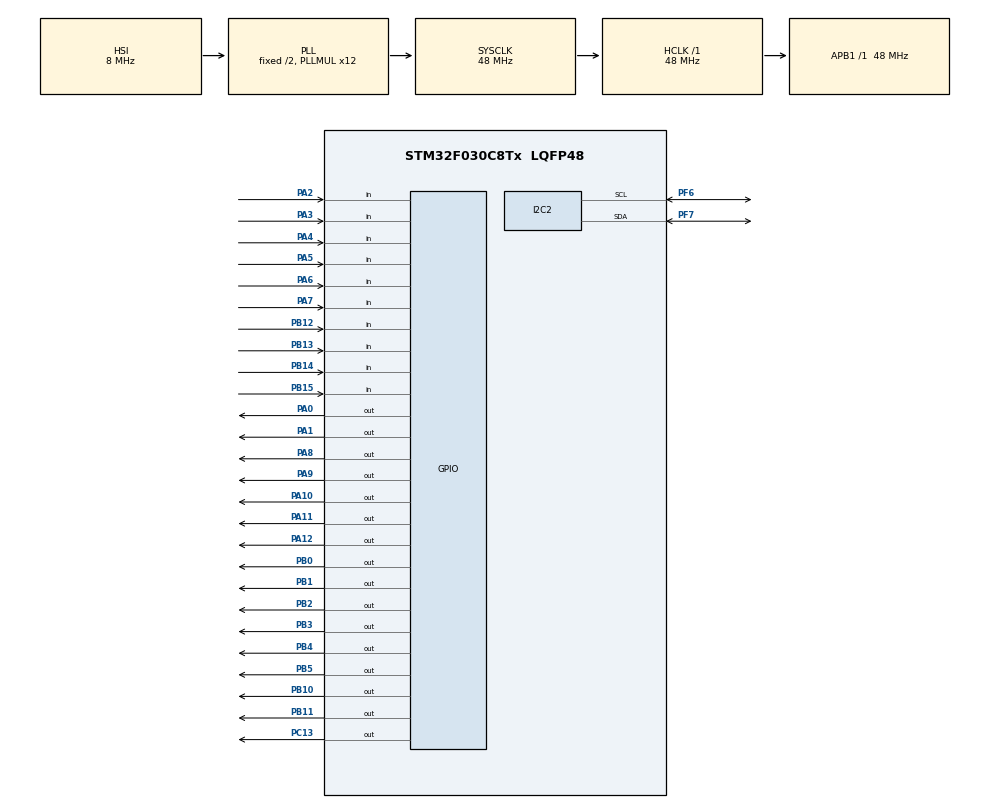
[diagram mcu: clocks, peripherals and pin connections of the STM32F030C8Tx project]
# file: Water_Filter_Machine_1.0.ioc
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I2C2.Timing=0x20303E5D
Mcu.Family=STM32F0
Mcu.Name=STM32F030C8Tx
Mcu.Package=LQFP48
PA0.Signal=GPIO_Output
PA1.Signal=GPIO_Output
PA10.Signal=GPIO_Output
PA11.Signal=GPIO_Output
PA12.Signal=GPIO_Output
PA13.Mode=Serial_Wire
PA13.Signal=SYS_SWDIO
PA14.Mode=Serial_Wire
PA14.Signal=SYS_SWCLK
PA2.Signal=GPIO_Input
PA3.Signal=GPIO_Input
PA4.Signal=GPIO_Input
PA5.Signal=GPIO_Input
PA6.Signal=GPIO_Input
PA7.Signal=GPIO_Input
PA8.Signal=GPIO_Output
PA9.Signal=GPIO_Output
PB0.Signal=GPIO_Output
PB1.Signal=GPIO_Output
PB10.Signal=GPIO_Output
PB11.Signal=GPIO_Output
PB12.GPIO_PuPd=GPIO_PULLUP
PB12.Signal=GPIO_Input
PB13.GPIO_PuPd=GPIO_PULLUP
PB13.Signal=GPIO_Input
PB14.GPIO_PuPd=GPIO_PULLUP
PB14.Signal=GPIO_Input
PB15.GPIO_PuPd=GPIO_PULLUP
PB15.Signal=GPIO_Input
PB2.Signal=GPIO_Output
PB3.Signal=GPIO_Output
PB4.Signal=GPIO_Output
PB5.Signal=GPIO_Output
PC13.Signal=GPIO_Output
PF6.Mode=I2C
PF6.Signal=I2C2_SCL
PF7.Mode=I2C
PF7.Signal=I2C2_SDA
ProjectManager.HeapSize=0x200
ProjectManager.StackSize=0x400
ProjectManager.TargetToolchain=STM32CubeIDE
RCC.AHBFreq_Value=48000000
RCC.APB1Freq_Value=48000000
RCC.APB1TimFreq_Value=48000000
RCC.HCLKFreq_Value=48000000
RCC.PLLMUL=RCC_PLL_MUL12
RCC.SYSCLKFreq_VALUE=48000000
RCC.SYSCLKSource=RCC_SYSCLKSOURCE_PLLCLK
board=custom

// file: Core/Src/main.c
/* USER CODE BEGIN Header */
/**
  ******************************************************************************
  * @file           : main.c
  * @brief          : Main program body
  ******************************************************************************
  * @attention
  *
  * Copyright (c) 2022 STMicroelectronics.
  * All rights reserved.
  *
  * This software is licensed under terms that can be found in the LICENSE file
  * in the root directory of this software component.
  * If no LICENSE file comes with this software, it is provided AS-IS.
  *
  ******************************************************************************
  */
/* USER CODE END Header */
#include "main.h"

/* USER CODE BEGIN Includes */

#include "Control.h"
#include "Menu.h"
#include "keypad_driver.h"

/* USER CODE END Includes */

I2C_HandleTypeDef hi2c2;

void SystemClock_Config(void);
static void MX_GPIO_Init(void);
static void MX_I2C2_Init(void);

int main(void)
{

  /* MCU Configuration--------------------------------------------------------*/

  /* Reset of all peripherals, Initializes the Flash interface and the Systick. */
  HAL_Init();

  /* Configure the system clock */
  SystemClock_Config();

  /* Initialize all configured peripherals */
  MX_GPIO_Init();
  MX_I2C2_Init();
  /* USER CODE BEGIN 2 */

  CONTRL_Init();
  MENU_Init();
  REALTIME_Init();

  /* USER CODE END 2 */

  /* Infinite loop */
  while (1)
  {

    /* USER CODE BEGIN 3 */

	  CONTROL_Handle();

	  MENU_Handle();

	  REALTIME_Handle();

	  KEYPAD_DRIVER_Handle();

//	  HAL_GPIO_WritePin(GPIOB, GPIO_PIN_0, 1);
//	  HAL_GPIO_WritePin(GPIOB, GPIO_PIN_1, 1);
//	  HAL_GPIO_WritePin(GPIOB, GPIO_PIN_2, 1);
//	  HAL_GPIO_WritePin(GPIOB, GPIO_PIN_10, 1);
//	  HAL_GPIO_WritePin(GPIOB, GPIO_PIN_11, 1);
//	  HAL_GPIO_WritePin(GPIOB, GPIO_PIN_0, 0);
//	  HAL_GPIO_WritePin(GPIOB, GPIO_PIN_1, 0);
//	  HAL_GPIO_WritePin(GPIOB, GPIO_PIN_2, 0);
//	  HAL_GPIO_WritePin(GPIOB, GPIO_PIN_10, 0);
//	  HAL_GPIO_WritePin(GPIOB, GPIO_PIN_11, 0);

  }
  /* USER CODE END 3 */
}

void SystemClock_Config(void)
{
  RCC_OscInitTypeDef RCC_OscInitStruct = {0};
  RCC_ClkInitTypeDef RCC_ClkInitStruct = {0};

  /** Initializes the RCC Oscillators according to the specified parameters
  * in the RCC_OscInitTypeDef structure.
  */
  RCC_OscInitStruct.OscillatorType = RCC_OSCILLATORTYPE_HSI;
  RCC_OscInitStruct.HSIState = RCC_HSI_ON;
  RCC_OscInitStruct.HSICalibrationValue = RCC_HSICALIBRATION_DEFAULT;
  RCC_OscInitStruct.PLL.PLLState = RCC_PLL_ON;
  RCC_OscInitStruct.PLL.PLLSource = RCC_PLLSOURCE_HSI;
  RCC_OscInitStruct.PLL.PLLMUL = RCC_PLL_MUL12;
  RCC_OscInitStruct.PLL.PREDIV = RCC_PREDIV_DIV1;
  if (HAL_RCC_OscConfig(&RCC_OscInitStruct) != HAL_OK)
  {
    Error_Handler();
  }

  /** Initializes the CPU, AHB and APB buses clocks
  */
  RCC_ClkInitStruct.ClockType = RCC_CLOCKTYPE_HCLK|RCC_CLOCKTYPE_SYSCLK
                              |RCC_CLOCKTYPE_PCLK1;
  RCC_ClkInitStruct.SYSCLKSource = RCC_SYSCLKSOURCE_PLLCLK;
  RCC_ClkInitStruct.AHBCLKDivider = RCC_SYSCLK_DIV1;
  RCC_ClkInitStruct.APB1CLKDivider = RCC_HCLK_DIV1;

  if (HAL_RCC_ClockConfig(&RCC_ClkInitStruct, FLASH_LATENCY_1) != HAL_OK)
  {
    Error_Handler();
  }
}

static void MX_I2C2_Init(void)
{

  hi2c2.Instance = I2C2;
  hi2c2.Init.Timing = 0x20303E5D;
  hi2c2.Init.OwnAddress1 = 0;
  hi2c2.Init.AddressingMode = I2C_ADDRESSINGMODE_7BIT;
  hi2c2.Init.DualAddressMode = I2C_DUALADDRESS_DISABLE;
  hi2c2.Init.OwnAddress2 = 0;
  hi2c2.Init.OwnAddress2Masks = I2C_OA2_NOMASK;
  hi2c2.Init.GeneralCallMode = I2C_GENERALCALL_DISABLE;
  hi2c2.Init.NoStretchMode = I2C_NOSTRETCH_DISABLE;
  if (HAL_I2C_Init(&hi2c2) != HAL_OK)
  {
    Error_Handler();
  }

  /** Configure Analogue filter
  */
  if (HAL_I2CEx_ConfigAnalogFilter(&hi2c2, I2C_ANALOGFILTER_ENABLE) != HAL_OK)
  {
    Error_Handler();
  }

  /** Configure Digital filter
  */
  if (HAL_I2CEx_ConfigDigitalFilter(&hi2c2, 0) != HAL_OK)
  {
    Error_Handler();
  }

}

static void MX_GPIO_Init(void)
{
  GPIO_InitTypeDef GPIO_InitStruct = {0};

  /* GPIO Ports Clock Enable */
  __HAL_RCC_GPIOC_CLK_ENABLE();
  __HAL_RCC_GPIOA_CLK_ENABLE();
  __HAL_RCC_GPIOB_CLK_ENABLE();
  __HAL_RCC_GPIOF_CLK_ENABLE();

  /*Configure GPIO pin Output Level */
  HAL_GPIO_WritePin(GPIOC, GPIO_PIN_13, GPIO_PIN_RESET);

  /*Configure GPIO pin Output Level */
  HAL_GPIO_WritePin(GPIOA, GPIO_PIN_0|GPIO_PIN_1|GPIO_PIN_8|GPIO_PIN_9
                          |GPIO_PIN_10|GPIO_PIN_11|GPIO_PIN_12, GPIO_PIN_RESET);

  /*Configure GPIO pin Output Level */
  HAL_GPIO_WritePin(GPIOB, GPIO_PIN_0|GPIO_PIN_1|GPIO_PIN_2|GPIO_PIN_10
                          |GPIO_PIN_11|GPIO_PIN_3|GPIO_PIN_4|GPIO_PIN_5, GPIO_PIN_RESET);

  /*Configure GPIO pin : PC13 */
  GPIO_InitStruct.Pin = GPIO_PIN_13;
  GPIO_InitStruct.Mode = GPIO_MODE_OUTPUT_PP;
  GPIO_InitStruct.Pull = GPIO_NOPULL;
  GPIO_InitStruct.Speed = GPIO_SPEED_FREQ_LOW;
  HAL_GPIO_Init(GPIOC, &GPIO_InitStruct);

  /*Configure GPIO pins : PA0 PA1 PA8 PA9
                           PA10 PA11 PA12 */
  GPIO_InitStruct.Pin = GPIO_PIN_0|GPIO_PIN_1|GPIO_PIN_8|GPIO_PIN_9
                          |GPIO_PIN_10|GPIO_PIN_11|GPIO_PIN_12;
  GPIO_InitStruct.Mode = GPIO_MODE_OUTPUT_PP;
  GPIO_InitStruct.Pull = GPIO_NOPULL;
  GPIO_InitStruct.Speed = GPIO_SPEED_FREQ_LOW;
  HAL_GPIO_Init(GPIOA, &GPIO_InitStruct);

  /*Configure GPIO pins : PA2 PA3 PA4 PA5
                           PA6 PA7 */
  GPIO_InitStruct.Pin = GPIO_PIN_2|GPIO_PIN_3|GPIO_PIN_4|GPIO_PIN_5
                          |GPIO_PIN_6|GPIO_PIN_7;
  GPIO_InitStruct.Mode = GPIO_MODE_INPUT;
  GPIO_InitStruct.Pull = GPIO_NOPULL;
  HAL_GPIO_Init(GPIOA, &GPIO_InitStruct);

  /*Configure GPIO pins : PB0 PB1 PB2 PB10
                           PB11 PB3 PB4 PB5 */
  GPIO_InitStruct.Pin = GPIO_PIN_0|GPIO_PIN_1|GPIO_PIN_2|GPIO_PIN_10
                          |GPIO_PIN_11|GPIO_PIN_3|GPIO_PIN_4|GPIO_PIN_5;
  GPIO_InitStruct.Mode = GPIO_MODE_OUTPUT_PP;
  GPIO_InitStruct.Pull = GPIO_NOPULL;
  GPIO_InitStruct.Speed = GPIO_SPEED_FREQ_LOW;
  HAL_GPIO_Init(GPIOB, &GPIO_InitStruct);

  /*Configure GPIO pins : PB12 PB13 PB14 PB15 */
  GPIO_InitStruct.Pin = GPIO_PIN_12|GPIO_PIN_13|GPIO_PIN_14|GPIO_PIN_15;
  GPIO_InitStruct.Mode = GPIO_MODE_INPUT;
  GPIO_InitStruct.Pull = GPIO_PULLUP;
  HAL_GPIO_Init(GPIOB, &GPIO_InitStruct);

}

void Error_Handler(void)
{
  __disable_irq();
  while (1)
  {
  }
}
